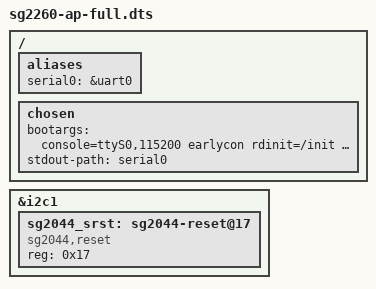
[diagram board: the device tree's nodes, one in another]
// SPDX-License-Identifier: (GPL-2.0 OR MIT)
/*
 * Copyright (C) 2022 Sophgo Technology Inc. All rights reserved.
 */

/dts-v1/;
#include <dt-bindings/interrupt-controller/irq.h>
#include <dt-bindings/reset/sophgo,sg2044-reset.h>
#include <dt-bindings/clock/sophgo,sg2044-clock.h>
#include "sg2260-cpu-ap.dtsi"
#include "sg2044-clock.dtsi"
#include "sg2260-peri-sys.dtsi"
#include "sg2260-tpu-sys.dtsi"
#include "sg2260-video-sys.dtsi"
#include "sg2044-pinctrl.dtsi"

/ {
	aliases {
		serial0 = &uart0;
	};

	chosen {
		bootargs = "console=ttyS0,115200 earlycon rdinit=/init root=/dev/ram0 rw initrd=0x8b000000,32M maxcpus=4 no5lvl";
		stdout-path = "serial0";
	};
};

&i2c1 {
	sg2044_srst: sg2044-reset@17 {
		compatible = "sg2044,reset";
		reg = <0x17>;
	};
};

